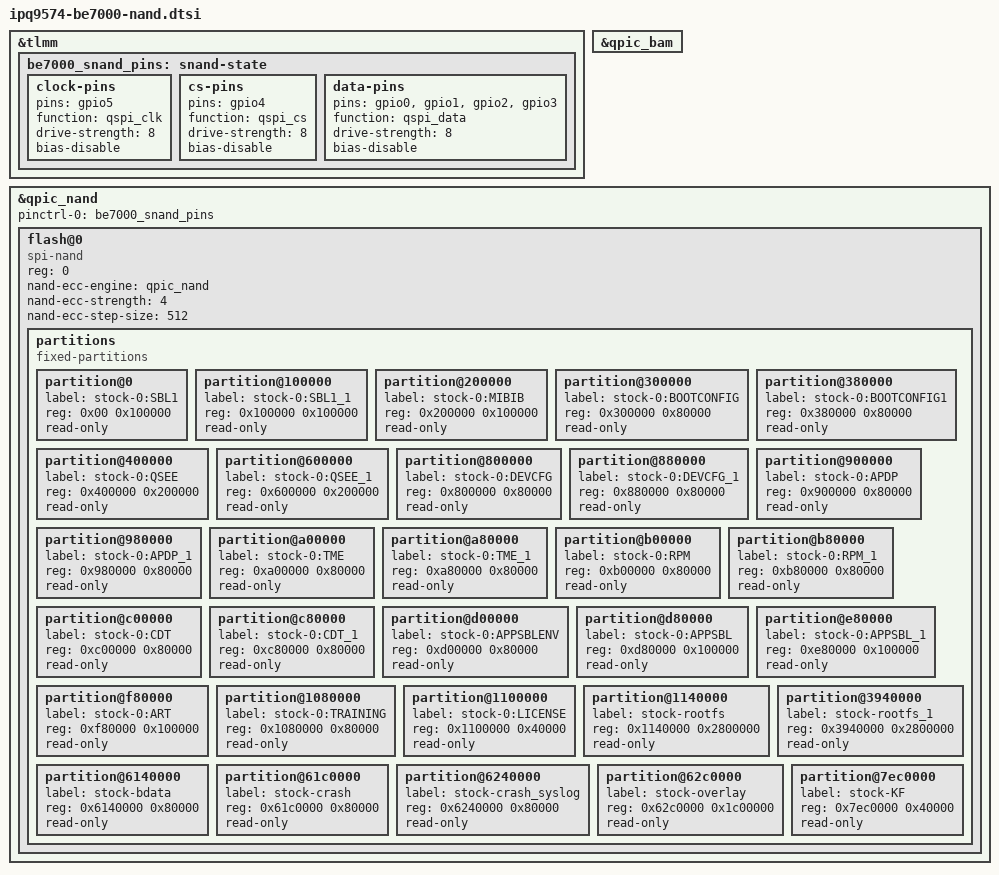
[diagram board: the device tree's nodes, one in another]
// SPDX-License-Identifier: (GPL-2.0+ OR BSD-3-Clause)
/* Xiaomi stock layout; expose MTD for read-only NAND bring-up, no UBI attach. */
&tlmm {
	be7000_snand_pins: snand-state {
		clock-pins {
			pins = "gpio5";
			function = "qspi_clk";
			drive-strength = <8>;
			bias-disable;
		};
		cs-pins {
			pins = "gpio4";
			function = "qspi_cs";
			drive-strength = <8>;
			bias-disable;
		};
		data-pins {
			pins = "gpio0", "gpio1", "gpio2", "gpio3";
			function = "qspi_data";
			drive-strength = <8>;
			bias-disable;
		};
	};
};

&qpic_bam {
	status = "okay";
};

&qpic_nand {
	pinctrl-0 = <&be7000_snand_pins>;
	pinctrl-names = "default";
	status = "okay";

	flash@0 {
		compatible = "spi-nand";
		reg = <0>;
		nand-ecc-engine = <&qpic_nand>;
		nand-ecc-strength = <4>;
		nand-ecc-step-size = <512>;

		partitions {
			compatible = "fixed-partitions";
			#address-cells = <1>;
			#size-cells = <1>;
			/* stock-* names avoid OpenWrt rootfs splitting and UBI auto-attach. */

			partition@0 {
				label = "stock-0:SBL1";
				reg = <0x00 0x100000>;
				read-only;
			};

			partition@100000 {
				label = "stock-0:SBL1_1";
				reg = <0x100000 0x100000>;
				read-only;
			};

			partition@200000 {
				label = "stock-0:MIBIB";
				reg = <0x200000 0x100000>;
				read-only;
			};

			partition@300000 {
				label = "stock-0:BOOTCONFIG";
				reg = <0x300000 0x80000>;
				read-only;
			};

			partition@380000 {
				label = "stock-0:BOOTCONFIG1";
				reg = <0x380000 0x80000>;
				read-only;
			};

			partition@400000 {
				label = "stock-0:QSEE";
				reg = <0x400000 0x200000>;
				read-only;
			};

			partition@600000 {
				label = "stock-0:QSEE_1";
				reg = <0x600000 0x200000>;
				read-only;
			};

			partition@800000 {
				label = "stock-0:DEVCFG";
				reg = <0x800000 0x80000>;
				read-only;
			};

			partition@880000 {
				label = "stock-0:DEVCFG_1";
				reg = <0x880000 0x80000>;
				read-only;
			};

			partition@900000 {
				label = "stock-0:APDP";
				reg = <0x900000 0x80000>;
				read-only;
			};

			partition@980000 {
				label = "stock-0:APDP_1";
				reg = <0x980000 0x80000>;
				read-only;
			};

			partition@a00000 {
				label = "stock-0:TME";
				reg = <0xa00000 0x80000>;
				read-only;
			};

			partition@a80000 {
				label = "stock-0:TME_1";
				reg = <0xa80000 0x80000>;
				read-only;
			};

			partition@b00000 {
				label = "stock-0:RPM";
				reg = <0xb00000 0x80000>;
				read-only;
			};

			partition@b80000 {
				label = "stock-0:RPM_1";
				reg = <0xb80000 0x80000>;
				read-only;
			};

			partition@c00000 {
				label = "stock-0:CDT";
				reg = <0xc00000 0x80000>;
				read-only;
			};

			partition@c80000 {
				label = "stock-0:CDT_1";
				reg = <0xc80000 0x80000>;
				read-only;
			};

			partition@d00000 {
				label = "stock-0:APPSBLENV";
				reg = <0xd00000 0x80000>;
				read-only;
			};

			partition@d80000 {
				label = "stock-0:APPSBL";
				reg = <0xd80000 0x100000>;
				read-only;
			};

			partition@e80000 {
				label = "stock-0:APPSBL_1";
				reg = <0xe80000 0x100000>;
				read-only;
			};

			partition@f80000 {
				label = "stock-0:ART";
				reg = <0xf80000 0x100000>;
				read-only;
			};

			partition@1080000 {
				label = "stock-0:TRAINING";
				reg = <0x1080000 0x80000>;
				read-only;
			};

			partition@1100000 {
				label = "stock-0:LICENSE";
				reg = <0x1100000 0x40000>;
				read-only;
			};

			partition@1140000 {
				label = "stock-rootfs";
				reg = <0x1140000 0x2800000>;
				read-only;
			};

			partition@3940000 {
				label = "stock-rootfs_1";
				reg = <0x3940000 0x2800000>;
				read-only;
			};

			partition@6140000 {
				label = "stock-bdata";
				reg = <0x6140000 0x80000>;
				read-only;
			};

			partition@61c0000 {
				label = "stock-crash";
				reg = <0x61c0000 0x80000>;
				read-only;
			};

			partition@6240000 {
				label = "stock-crash_syslog";
				reg = <0x6240000 0x80000>;
				read-only;
			};

			partition@62c0000 {
				label = "stock-overlay";
				reg = <0x62c0000 0x1c00000>;
				read-only;
			};

			partition@7ec0000 {
				label = "stock-KF";
				reg = <0x7ec0000 0x40000>;
				read-only;
			};
		};
	};
};
